# CC430F5123 register map
Registers are 16-bit, read-write, reset 0x0 unless marked. A register's access mark holds for its fields unless they carry their own. Offsets are from the block's base; [hi:lo] are bit positions; {n}, {i} and the like mark numbered series.

## MPY_32_Multiplier_32_Bit_Mode
Base 0x00000000
0x4D0 MPY32L — 32-bit operand 1 - multiply - low word
0x4D2 MPY32H — 32-bit operand 1 - multiply - high word
0x4D4 MPYS32L — 32-bit operand 1 - signed multiply - low word
0x4D6 MPYS32H — 32-bit operand 1 - signed multiply - high word
0x4D8 MAC32L — 32-bit operand 1 - multiply accumulate - low word
0x4DA MAC32H — 32-bit operand 1 - multiply accumulate - high word
0x4DC MACS32L — 32-bit operand 1 - signed multiply accumulate - low word
0x4DE MACS32H — 32-bit operand 1 - signed multiply accumulate - high word
0x4E0 OP2L — 32-bit operand 2 - low word
0x4E2 OP2H — 32-bit operand 2 - high word
0x4E4 RES0 — 32x32-bit result 0 - least significant word
0x4E6 RES1 — 32x32-bit result 1
0x4E8 RES2 — 32x32-bit result 2
0x4EA RES3 — 32x32-bit result 3 - most significant word

## Port_A
Base 0x00000000
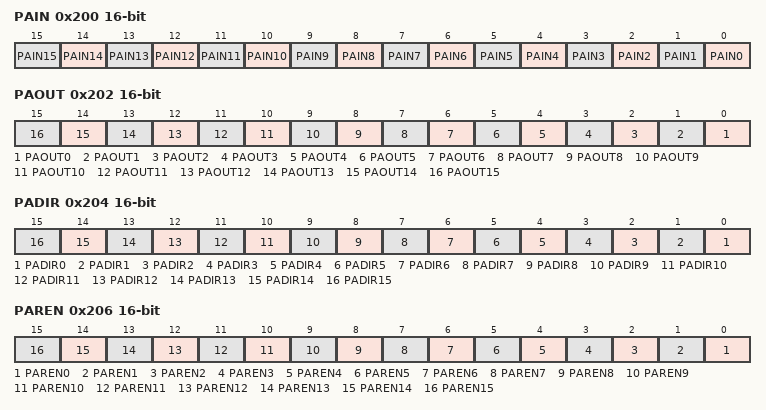
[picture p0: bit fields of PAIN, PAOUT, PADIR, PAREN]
0x200 PAIN — Port A Input
  [n] PAIN{n} (n=0..15)
0x202 PAOUT — Port A Output
  [n] PAOUT{n} (n=0..15)
0x204 PADIR — Port A Direction
  [n] PADIR{n} (n=0..15)
0x206 PAREN — Port A Resistor Enable
  [n] PAREN{n} (n=0..15)
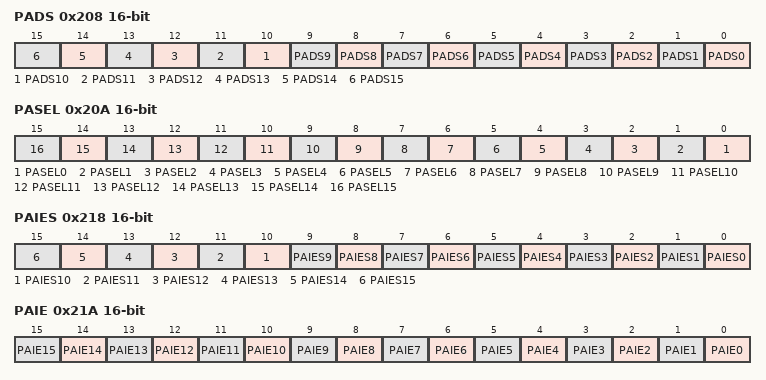
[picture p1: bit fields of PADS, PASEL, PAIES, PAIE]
0x208 PADS — Port A Drive Strenght
  [n] PADS{n} (n=0..15)
0x20A PASEL — Port A Selection
  [n] PASEL{n} (n=0..15)
0x218 PAIES — Port A Interrupt Edge Select
  [n] PAIES{n} (n=0..15)
0x21A PAIE — Port A Interrupt Enable
  [n] PAIE{n} (n=0..15)
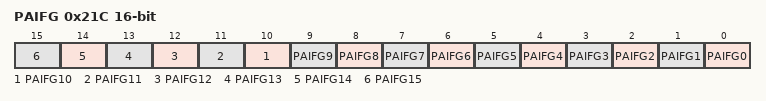
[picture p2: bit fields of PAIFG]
0x21C PAIFG — Port A Interrupt Flag
  [n] PAIFG{n} (n=0..15)

## Port_1_2
Base 0x00000000
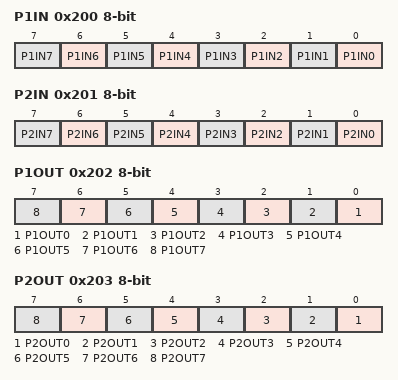
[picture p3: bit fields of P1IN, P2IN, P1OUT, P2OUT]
0x200 P1IN 8-bit — Port 1 Input
  [n] P1IN{n} (n=0..7)
0x201 P2IN 8-bit — Port 2 Input
  [n] P2IN{n} (n=0..7)
0x202 P1OUT 8-bit — Port 1 Output
  [n] P1OUT{n} (n=0..7)
0x203 P2OUT 8-bit — Port 2 Output
  [n] P2OUT{n} (n=0..7)
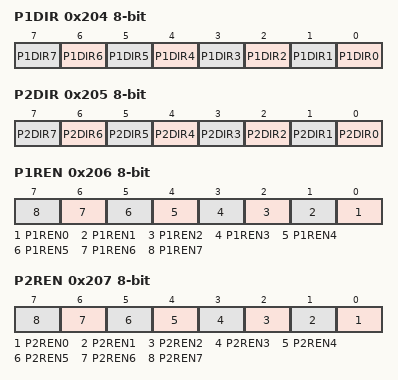
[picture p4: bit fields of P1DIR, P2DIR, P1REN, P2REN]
0x204 P1DIR 8-bit — Port 1 Direction
  [n] P1DIR{n} (n=0..7)
0x205 P2DIR 8-bit — Port 2 Direction
  [n] P2DIR{n} (n=0..7)
0x206 P1REN 8-bit — Port 1 Resistor Enable
  [n] P1REN{n} (n=0..7)
0x207 P2REN 8-bit — Port 2 Resistor Enable
  [n] P2REN{n} (n=0..7)
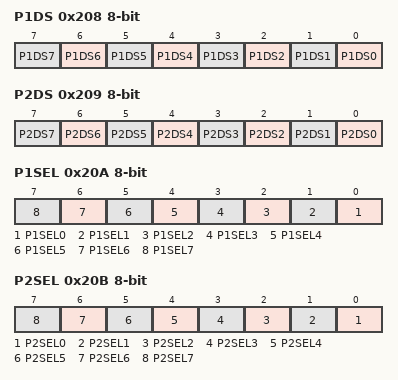
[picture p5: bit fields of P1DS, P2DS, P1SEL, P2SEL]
0x208 P1DS 8-bit — Port 1 Drive Strenght
  [n] P1DS{n} (n=0..7)
0x209 P2DS 8-bit — Port 2 Drive Strenght
  [n] P2DS{n} (n=0..7)
0x20A P1SEL 8-bit — Port 1 Selection
  [n] P1SEL{n} (n=0..7)
0x20B P2SEL 8-bit — Port 2 Selection
  [n] P2SEL{n} (n=0..7)
0x20E P1IV — Port 1 Interrupt Vector Word
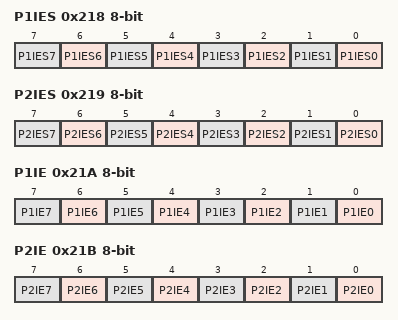
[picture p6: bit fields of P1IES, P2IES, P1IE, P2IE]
0x218 P1IES 8-bit — Port 1 Interrupt Edge Select
  [n] P1IES{n} (n=0..7)
0x219 P2IES 8-bit — Port 2 Interrupt Edge Select
  [n] P2IES{n} (n=0..7)
0x21A P1IE 8-bit — Port 1 Interrupt Enable
  [n] P1IE{n} (n=0..7)
0x21B P2IE 8-bit — Port 2 Interrupt Enable
  [n] P2IE{n} (n=0..7)
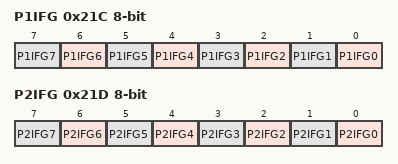
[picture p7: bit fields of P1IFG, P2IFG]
0x21C P1IFG 8-bit — Port 1 Interrupt Flag
  [n] P1IFG{n} (n=0..7)
0x21D P2IFG 8-bit — Port 2 Interrupt Flag
  [n] P2IFG{n} (n=0..7)
0x21E P2IV — Port 2 Interrupt Vector Word

## Port_B
Base 0x00000000
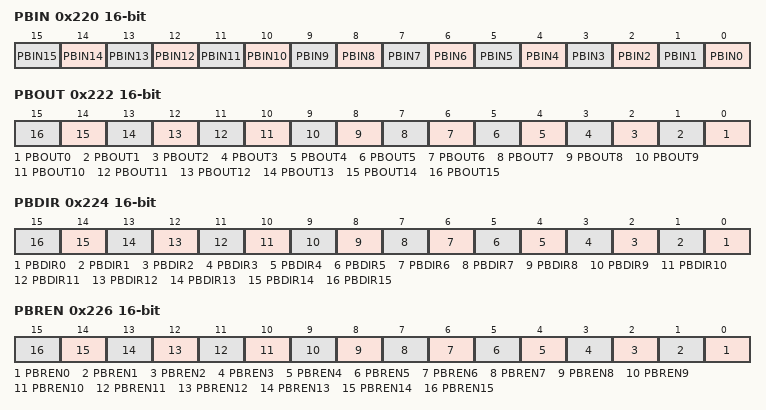
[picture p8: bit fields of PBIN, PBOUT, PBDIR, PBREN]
0x220 PBIN — Port B Input
  [n] PBIN{n} (n=0..15)
0x222 PBOUT — Port B Output
  [n] PBOUT{n} (n=0..15)
0x224 PBDIR — Port B Direction
  [n] PBDIR{n} (n=0..15)
0x226 PBREN — Port B Resistor Enable
  [n] PBREN{n} (n=0..15)
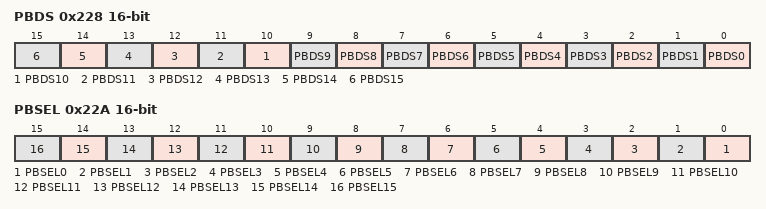
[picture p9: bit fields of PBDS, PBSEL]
0x228 PBDS — Port B Drive Strenght
  [n] PBDS{n} (n=0..15)
0x22A PBSEL — Port B Selection
  [n] PBSEL{n} (n=0..15)

## Port_3_4
Base 0x00000000
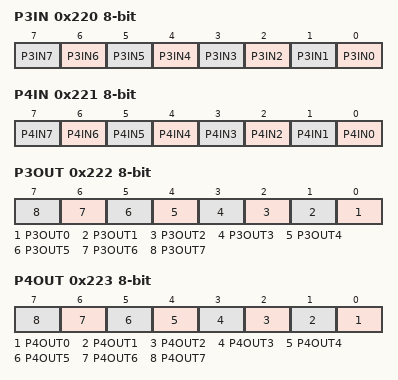
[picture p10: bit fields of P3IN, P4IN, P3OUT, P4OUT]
0x220 P3IN 8-bit — Port 3 Input
  [n] P3IN{n} (n=0..7)
0x221 P4IN 8-bit — Port 4 Input
  [n] P4IN{n} (n=0..7)
0x222 P3OUT 8-bit — Port 3 Output
  [n] P3OUT{n} (n=0..7)
0x223 P4OUT 8-bit — Port 4 Output
  [n] P4OUT{n} (n=0..7)
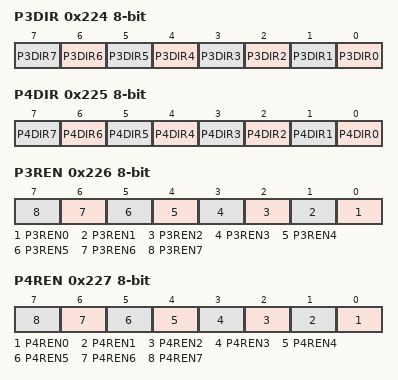
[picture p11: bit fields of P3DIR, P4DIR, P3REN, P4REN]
0x224 P3DIR 8-bit — Port 3 Direction
  [n] P3DIR{n} (n=0..7)
0x225 P4DIR 8-bit — Port 4 Direction
  [n] P4DIR{n} (n=0..7)
0x226 P3REN 8-bit — Port 3 Resistor Enable
  [n] P3REN{n} (n=0..7)
0x227 P4REN 8-bit — Port 4 Resistor Enable
  [n] P4REN{n} (n=0..7)
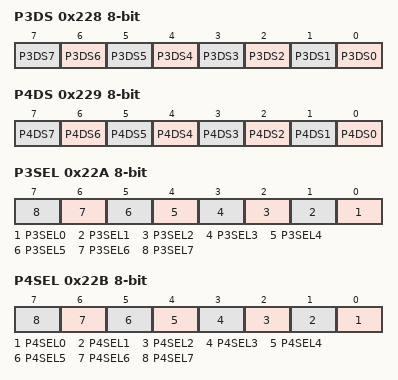
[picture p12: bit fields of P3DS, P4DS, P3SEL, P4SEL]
0x228 P3DS 8-bit — Port 3 Drive Strenght
  [n] P3DS{n} (n=0..7)
0x229 P4DS 8-bit — Port 4 Drive Strenght
  [n] P4DS{n} (n=0..7)
0x22A P3SEL 8-bit — Port 3 Selection
  [n] P3SEL{n} (n=0..7)
0x22B P4SEL 8-bit — Port 4 Selection
  [n] P4SEL{n} (n=0..7)
